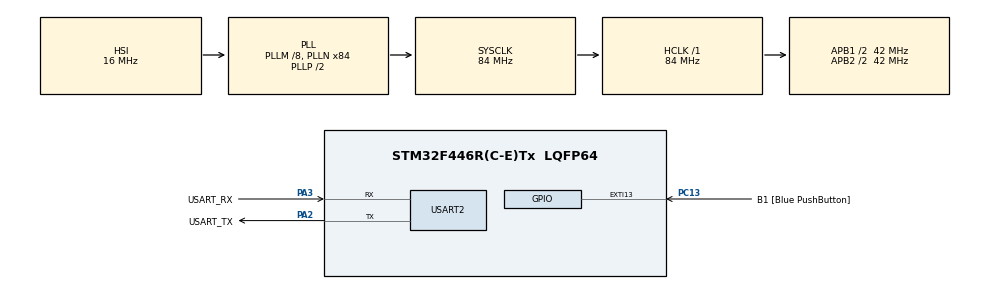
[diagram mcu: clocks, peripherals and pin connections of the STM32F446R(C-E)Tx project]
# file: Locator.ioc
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Mcu.Family=STM32F4
Mcu.Name=STM32F446R(C-E)Tx
Mcu.Package=LQFP64
NVIC.PriorityGroup=NVIC_PRIORITYGROUP_0
PA13.GPIO_Label=TMS
PA13.Mode=Serial_Wire
PA13.Signal=SYS_JTMS-SWDIO
PA14.GPIO_Label=TCK
PA14.Mode=Serial_Wire
PA14.Signal=SYS_JTCK-SWCLK
PA2.GPIO_Label=USART_TX
PA2.Mode=Asynchronous
PA2.Signal=USART2_TX
PA3.GPIO_Label=USART_RX
PA3.Mode=Asynchronous
PA3.Signal=USART2_RX
PA5.Signal=COMP_DAC2_group
PB3.GPIO_Label=SWO
PB3.Signal=SYS_JTDO-SWO
PC13.GPIO_Label=B1 [Blue PushButton]
PC13.GPIO_ModeDefaultEXTI=GPIO_MODE_IT_FALLING
PC13.Signal=GPXTI13
PC14-OSC32_IN.Mode=LSE-External-Oscillator
PC14-OSC32_IN.Signal=RCC_OSC32_IN
PC15-OSC32_OUT.Mode=LSE-External-Oscillator
PC15-OSC32_OUT.Signal=RCC_OSC32_OUT
PH0-OSC_IN.Mode=HSE-External-Oscillator
PH0-OSC_IN.Signal=RCC_OSC_IN
PH1-OSC_OUT.Mode=HSE-External-Oscillator
PH1-OSC_OUT.Signal=RCC_OSC_OUT
ProjectManager.HeapSize=0x200
ProjectManager.StackSize=0x400
ProjectManager.TargetToolchain=STM32CubeIDE
RCC.48MHZClocksFreq_Value=84000000
RCC.AHBFreq_Value=84000000
RCC.APB1CLKDivider=RCC_HCLK_DIV2
RCC.APB1Freq_Value=42000000
RCC.APB1TimFreq_Value=84000000
RCC.APB2CLKDivider=RCC_HCLK_DIV2
RCC.APB2Freq_Value=42000000
RCC.APB2TimFreq_Value=84000000
RCC.CortexFreq_Value=84000000
RCC.FLatency-AdvancedSettings=FLASH_LATENCY_2
RCC.HCLKFreq_Value=84000000
RCC.HSE_VALUE=8000000
RCC.HSI_VALUE=16000000
RCC.PLLM=8
RCC.PLLN=84
RCC.SYSCLKFreq_VALUE=84000000
RCC.SYSCLKSource=RCC_SYSCLKSOURCE_PLLCLK
RCC.USBFreq_Value=84000000
RCC.VCOOutputFreq_Value=168000000
SH.COMP_DAC2_group.0=DAC_OUT2
USART2.VirtualMode=VM_ASYNC
board=NUCLEO-F446RE

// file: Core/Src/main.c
/* USER CODE BEGIN Header */
/**
  ******************************************************************************
  * @file           : main.c
  * @brief          : Main program body
  ******************************************************************************
  * @attention
  *
  * <h2><center>&copy; Copyright (c) 2021 STMicroelectronics.
  * All rights reserved.</center></h2>
  *
  * This software component is licensed by ST under BSD 3-Clause license,
  * the "License"; You may not use this file except in compliance with the
  * License. You may obtain a copy of the License at:
  *                        opensource.org/licenses/BSD-3-Clause
  *
  ******************************************************************************
  */
/* USER CODE END Header */
#include "main.h"

/* USER CODE BEGIN Includes */
#include <stdlib.h>
#include <math.h>
#include  <errno.h>
#include <string.h>
#include  <sys/unistd.h> // STDOUT_FILENO, STDERR_FILENO
#include "arm_math.h"

/* USER CODE END Includes */

/* USER CODE BEGIN PD */
#define SAMPLES 1024
#define SIN_SAMPLING_RATE 9000
#define SIN_FREQUENCY 20
/* USER CODE END PD */

UART_HandleTypeDef huart2;

/* USER CODE BEGIN PV */
float32_t fL = 20;
float32_t fH = 2000;
/* USER CODE END PV */

void SystemClock_Config(void);
static void MX_GPIO_Init(void);
static void MX_USART2_UART_Init(void);
/* USER CODE BEGIN PFP */
static void to_float(uint32_t*, float32_t*, uint32_t);
static float32_t do_fft(uint32_t* ADC_a, uint32_t* ADC_b);

/* USER CODE END PFP */

/* USER CODE BEGIN 0 */
uint32_t ADC_top[SAMPLES];
uint32_t ADC_bottom[SAMPLES];
uint32_t ADC_right[SAMPLES];
uint32_t ADC_left[SAMPLES];

arm_cfft_instance_f32 fft_instance;

uint8_t startLocating = 1;

/* USER CODE END 0 */

int main(void)
{

  /* MCU Configuration--------------------------------------------------------*/

  /* Reset of all peripherals, Initializes the Flash interface and the Systick. */
  HAL_Init();

  /* USER CODE BEGIN Init */
  arm_cfft_init_f32(&fft_instance, SAMPLES);

//  arm_cfft_f32(&fft_instance, testInput_f32_10khz, 0, 1);
//  arm_cmplx_mag_f32(testInput_f32_10khz, testOutput, 2048);
//  float32_t maxValue;
//  int testIndex;
//  arm_max_f32(testOutput, 1024, &maxValue, &testIndex);
//
//  int idx = (int)(1.0 / (SIN_SAMPLES / SAMPLES));

  /* USER CODE END Init */

  /* Configure the system clock */
  SystemClock_Config();

  /* Initialize all configured peripherals */
  MX_GPIO_Init();
  MX_USART2_UART_Init();

  /* Infinite loop */
  /* USER CODE BEGIN WHILE */

  for(int i = 0; i < SAMPLES; i++) {
	  ADC_top[i] = ADC_right[i] = (uint32_t) ((sin(2 * M_PI * SIN_FREQUENCY * ((double)i / SIN_SAMPLING_RATE)) + 1) * (double) ((1023 + 1) / 2));
	  ADC_bottom[i] = ADC_left[i] = (uint32_t) ((sin(2 * M_PI * SIN_FREQUENCY * ((double)i / SIN_SAMPLING_RATE) + M_PI / 32) + 1) * (double) ((1023 + 1) / 2));

  }

  while (1)
  {

	  uint8_t command;
	  HAL_StatusTypeDef status = HAL_UART_Receive(&huart2, &command, 1, 0);

	  if(status == HAL_UART_ERROR_NONE && command == 3) {
		  uint8_t fLSetting[sizeof(uint32_t)];
		  if(HAL_UART_Receive(&huart2, fLSetting, sizeof(uint32_t), 0) == HAL_UART_ERROR_NONE) {
			  fL = fLSetting[3] << 24 | fLSetting[2] << 16 | fLSetting[1] << 8 | fLSetting[0];
		  }

		  uint8_t fHSetting[sizeof(uint32_t)];
		  if(HAL_UART_Receive(&huart2, fHSetting, sizeof(uint32_t), 0) == HAL_UART_ERROR_NONE) {
			  fL = fHSetting[3] << 24 | fHSetting[2] << 16 | fHSetting[1] << 8 | fHSetting[0];
		  }

	  }
	  if(status == HAL_UART_ERROR_NONE && command == 5) {
		  startLocating = 1;
	  }
	  if(status == HAL_UART_ERROR_NONE && command == 6) {
		  startLocating = 0;
	  }

	  if(startLocating) {

		  uint32_t start = HAL_GetTick();

		  float32_t diff_tb = do_fft(ADC_top, ADC_bottom);
		  float32_t diff_lr = do_fft(ADC_right, ADC_left);

		  uint32_t end = HAL_GetTick();

		  uint32_t elapsed = end - start;
		  elapsed++;

	  }
    /* USER CODE END WHILE */

  }
}

void SystemClock_Config(void)
{
  RCC_OscInitTypeDef RCC_OscInitStruct = {0};
  RCC_ClkInitTypeDef RCC_ClkInitStruct = {0};

  /** Configure the main internal regulator output voltage
  */
  __HAL_RCC_PWR_CLK_ENABLE();
  __HAL_PWR_VOLTAGESCALING_CONFIG(PWR_REGULATOR_VOLTAGE_SCALE3);
  /** Initializes the RCC Oscillators according to the specified parameters
  * in the RCC_OscInitTypeDef structure.
  */
  RCC_OscInitStruct.OscillatorType = RCC_OSCILLATORTYPE_HSI;
  RCC_OscInitStruct.HSIState = RCC_HSI_ON;
  RCC_OscInitStruct.HSICalibrationValue = RCC_HSICALIBRATION_DEFAULT;
  RCC_OscInitStruct.PLL.PLLState = RCC_PLL_ON;
  RCC_OscInitStruct.PLL.PLLSource = RCC_PLLSOURCE_HSI;
  RCC_OscInitStruct.PLL.PLLM = 8;
  RCC_OscInitStruct.PLL.PLLN = 84;
  RCC_OscInitStruct.PLL.PLLP = RCC_PLLP_DIV2;
  RCC_OscInitStruct.PLL.PLLQ = 2;
  RCC_OscInitStruct.PLL.PLLR = 2;
  if (HAL_RCC_OscConfig(&RCC_OscInitStruct) != HAL_OK)
  {
    Error_Handler();
  }
  /** Initializes the CPU, AHB and APB buses clocks
  */
  RCC_ClkInitStruct.ClockType = RCC_CLOCKTYPE_HCLK|RCC_CLOCKTYPE_SYSCLK
                              |RCC_CLOCKTYPE_PCLK1|RCC_CLOCKTYPE_PCLK2;
  RCC_ClkInitStruct.SYSCLKSource = RCC_SYSCLKSOURCE_PLLCLK;
  RCC_ClkInitStruct.AHBCLKDivider = RCC_SYSCLK_DIV1;
  RCC_ClkInitStruct.APB1CLKDivider = RCC_HCLK_DIV2;
  RCC_ClkInitStruct.APB2CLKDivider = RCC_HCLK_DIV2;

  if (HAL_RCC_ClockConfig(&RCC_ClkInitStruct, FLASH_LATENCY_2) != HAL_OK)
  {
    Error_Handler();
  }
}

static void MX_USART2_UART_Init(void)
{

  huart2.Instance = USART2;
  huart2.Init.BaudRate = 115200;
  huart2.Init.WordLength = UART_WORDLENGTH_8B;
  huart2.Init.StopBits = UART_STOPBITS_1;
  huart2.Init.Parity = UART_PARITY_NONE;
  huart2.Init.Mode = UART_MODE_TX_RX;
  huart2.Init.HwFlowCtl = UART_HWCONTROL_NONE;
  huart2.Init.OverSampling = UART_OVERSAMPLING_16;
  if (HAL_UART_Init(&huart2) != HAL_OK)
  {
    Error_Handler();
  }

}

static void MX_GPIO_Init(void)
{
  GPIO_InitTypeDef GPIO_InitStruct = {0};

  /* GPIO Ports Clock Enable */
  __HAL_RCC_GPIOC_CLK_ENABLE();
  __HAL_RCC_GPIOH_CLK_ENABLE();
  __HAL_RCC_GPIOA_CLK_ENABLE();
  __HAL_RCC_GPIOB_CLK_ENABLE();

  /*Configure GPIO pin : B1_Pin */
  GPIO_InitStruct.Pin = B1_Pin;
  GPIO_InitStruct.Mode = GPIO_MODE_IT_FALLING;
  GPIO_InitStruct.Pull = GPIO_NOPULL;
  HAL_GPIO_Init(B1_GPIO_Port, &GPIO_InitStruct);

  /*Configure GPIO pin : PA5 */
  GPIO_InitStruct.Pin = GPIO_PIN_5;
  GPIO_InitStruct.Mode = GPIO_MODE_ANALOG;
  GPIO_InitStruct.Pull = GPIO_NOPULL;
  HAL_GPIO_Init(GPIOA, &GPIO_InitStruct);

}

/* USER CODE BEGIN 4 */
int _write(int file, char *data, int len)
{
   if ((file != STDOUT_FILENO) && (file != STDERR_FILENO))
   {
      errno = EBADF;
      return -1;
   }

   // arbitrary timeout 1000
   HAL_StatusTypeDef status =
      HAL_UART_Transmit(&huart2, (uint8_t*)data, len, 1000);

   // return # of bytes written - as best we can tell
   return (status == HAL_OK ? len : 0);
}

//void PollChannel(ADC_HandleTypeDef* hadcA, ADC_HandleTypeDef* hadcB, uint32_t channelA, uint32_t channelB, uint32_t* aValue, uint32_t* bValue) {
//	ADC_ChannelConfTypeDef sConfig = {0};
//
//	sConfig.Channel = channelA;
//	sConfig.Rank = 1;
//	sConfig.SamplingTime = ADC_SAMPLETIME_3CYCLES;
//
//	HAL_ADC_ConfigChannel(hadcA, &sConfig);
//
//	sConfig.Channel = channelB;
//	sConfig.Rank = 1;
//	sConfig.SamplingTime = ADC_SAMPLETIME_3CYCLES;
//
//	HAL_ADC_ConfigChannel(hadcB, &sConfig);
//	HAL_ADC_Start(hadcA);
//	HAL_ADC_Start(hadcB);
//
//	HAL_ADC_PollForConversion(hadcA, 1000);
//	HAL_ADC_PollForConversion(hadcB, 1000);
//	*aValue = HAL_ADC_GetValue(hadcA);
//	*bValue = HAL_ADC_GetValue(hadcB);
//}
//void HAL_TIM_PeriodElapsedCallback(TIM_HandleTypeDef* htim) {
//	if(htim == &htim4) {
//		uint32_t top_sample;
//		uint32_t bottom_sample;
//		uint32_t right_sample;
//		uint32_t left_sample;
//
//		PollChannel(&hadc1, &hadc2, ADC_CHANNEL_0, ADC_CHANNEL_6, &top_sample, &bottom_sample);
//		PollChannel(&hadc1, &hadc2, ADC_CHANNEL_1, ADC_CHANNEL_7, &right_sample, &left_sample);
//		printf("%d: %d %d %d %d\n\r", si, top_sample, bottom_sample, right_sample, left_sample);
//		ADC_top[si] = top_sample;
//		ADC_bottom[si] = bottom_sample;
//		ADC_right[si] = right_sample;
//		ADC_left[si] = left_sample;
//		if(si == SAMPLES - 1) {
//			float32_t top_float[SAMPLES];
//			float32_t top_mag[SAMPLES / 2];
//			float32_t top_phase[SAMPLES / 2];
//
//			float32_t bottom_float[SAMPLES];
//			float32_t bottom_mag[SAMPLES / 2];
//			float32_t bottom_phase[SAMPLES / 2];
//
//			to_float(ADC_top, top_float, SAMPLES);
//			to_float(ADC_bottom, bottom_float, SAMPLES);
//
//			do_fft(top_float, top_phase, top_mag, SAMPLES);
//			do_fft(bottom_float, bottom_phase, bottom_mag, SAMPLES);
//
//		}
//		si = (si + 1) % SAMPLES;
//
//
//	}
//}
float32_t a_float[SAMPLES];
float32_t b_float[SAMPLES];
float32_t a_mag[SAMPLES / 2];
float32_t a_phase[SAMPLES / 2];
float32_t b_phase[SAMPLES / 2];

float32_t do_fft(uint32_t* ADC_a, uint32_t* ADC_b) {
	memset(a_float, 0, SAMPLES * sizeof(float32_t));
	memset(b_float, 0, SAMPLES  * sizeof(float32_t));
	memset(a_mag, 0, SAMPLES / 2  * sizeof(float32_t));
	memset(a_phase, 0, SAMPLES / 2  * sizeof(float32_t));
	memset(b_phase, 0, SAMPLES / 2  * sizeof(float32_t));
	to_float(ADC_a, a_float, SAMPLES);
	to_float(ADC_b, b_float, SAMPLES);

	arm_cfft_init_f32(&fft_instance, SAMPLES);
	arm_cfft_f32(&fft_instance, a_float, 0, 1);
	arm_cmplx_mag_f32(a_float, a_mag, SAMPLES / 2);

	//calculate phase for each bin
	for(int i = 0; i < SAMPLES; i+=2) {
		a_phase[i/2] = atan(a_float[i + 1] / a_float[i]);
	}

	arm_cfft_init_f32(&fft_instance, SAMPLES);
	arm_cfft_f32(&fft_instance, b_float, 0, 1);

	//calculate phase for each bin
	for(int i = 0; i < SAMPLES; i+=2) {
		b_phase[i/2] = atan(b_float[i + 1] / b_float[i]);
	}

	float32_t max;
	uint32_t index;
	arm_max_f32(a_mag, SAMPLES / 2, &max, &index);

	int frequency = (index * SIN_SAMPLING_RATE) / SAMPLES / 2;
	if(frequency >= fL && frequency <= fH) {
		float32_t a_phase_max = a_phase[index];
		float32_t b_phase_max = b_phase[index];
		float32_t tb_t_diff = ((a_phase_max - b_phase_max) * SAMPLES)/(2 * M_PI);
		return tb_t_diff;
	}
	return NAN;

}

void to_float(uint32_t* int_array, float32_t* float_array, uint32_t length) {

	for(int i = 0; i < length; i++) {
		float_array[i] = ((float32_t)int_array[i] / (1024.0 / 2)) - 1;
	}
}
/* USER CODE END 4 */

void Error_Handler(void)
{
  __disable_irq();
  while (1)
  {
  }
}

/************************ (C) COPYRIGHT STMicroelectronics *****END OF FILE****/
